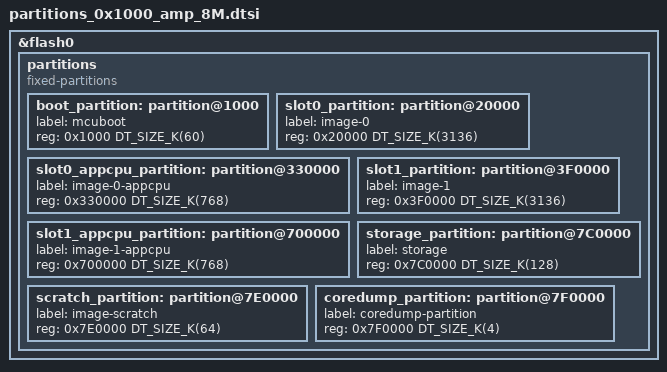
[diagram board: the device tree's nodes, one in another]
/*
 * Copyright (c) 2024 Espressif Systems (Shanghai) Co., Ltd.
 *
 * SPDX-License-Identifier: Apache-2.0
 */

 /* 8MB flash partition table */
&flash0 {
	partitions {
		compatible = "fixed-partitions";
		#address-cells = <1>;
		#size-cells = <1>;

		boot_partition: partition@1000 {
			label = "mcuboot";
			reg = <0x1000 DT_SIZE_K(60)>;
		};

		slot0_partition: partition@20000 {
			label = "image-0";
			reg = <0x20000 DT_SIZE_K(3136)>;
		};

		slot0_appcpu_partition: partition@330000 {
			label = "image-0-appcpu";
			reg = <0x330000 DT_SIZE_K(768)>;
		};

		slot1_partition: partition@3F0000 {
			label = "image-1";
			reg = <0x3F0000 DT_SIZE_K(3136)>;
		};

		slot1_appcpu_partition: partition@700000 {
			label = "image-1-appcpu";
			reg = <0x700000 DT_SIZE_K(768)>;
		};

		storage_partition: partition@7C0000 {
			label = "storage";
			reg = <0x7C0000 DT_SIZE_K(128)>;
		};

		scratch_partition: partition@7E0000 {
			   label = "image-scratch";
			   reg = <0x7E0000 DT_SIZE_K(64)>;
		};

		coredump_partition: partition@7F0000 {
			label = "coredump-partition";
			reg = <0x7F0000 DT_SIZE_K(4)>;
		};
	};
};
